CM_ "IMPORT _honda_common.dbc";
CM_ "IMPORT _bosch_2018.dbc";
CM_ "IMPORT _bosch_adas_2018.dbc";
CM_ "IMPORT _bosch_standstill.dbc";
CM_ "IMPORT _steering_sensors_b.dbc";

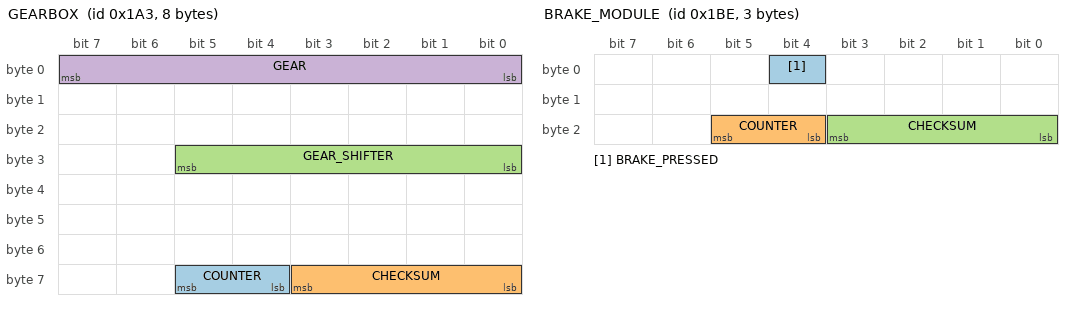
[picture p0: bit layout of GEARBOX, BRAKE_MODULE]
BO_ 419 GEARBOX: 8 PCM
 SG_ COUNTER : 61|2@0+ (1,0) [0|3] "" EON
 SG_ CHECKSUM : 59|4@0+ (1,0) [0|3] "" EON
 SG_ GEAR_SHIFTER : 29|6@0+ (1,0) [0|63] "" EON
 SG_ GEAR : 7|8@0+ (1,0) [0|255] "" EON

BO_ 446 BRAKE_MODULE: 3 VSA
 SG_ BRAKE_PRESSED : 4|1@0+ (1,0) [0|1] "" XXX
 SG_ COUNTER : 21|2@0+ (1,0) [0|3] "" XXX
 SG_ CHECKSUM : 19|4@0+ (1,0) [0|15] "" XXX

VAL_ 419 GEAR_SHIFTER  32 "D" 8 "R" 4 "P" ;
VAL_ 545 ECON_ON_2 0 "off" 3 "on" ;
